VERSION ""

NS_ :

BS_:

BU_: D153 VCU

BO_ 3221225472 VECTOR__INDEPENDENT_SIG_MSG: 0 Vector__XXX
 SG_ VCU_dcBusVoltage : 0|16@0+ (1,0) [0|65535] "" Vector__XXX

BO_ 7 VCU_throttleRegen: 2 VCU
 SG_ VCU_regenPercent : 15|8@0- (1,0) [-128|127] ""  D153
 SG_ VCU_throttlePercent : 7|8@0+ (1,0) [0|255] ""  D153

BO_ 6 VCU_torqueInfo: 4 VCU
 SG_ VCU_throttlePedalTorqueMap : 23|16@0+ (1,0) [0|65535] ""  D153
 SG_ VCU_throttleMapAimSwitch : 7|8@0+ (1,0) [0|255] ""  D153

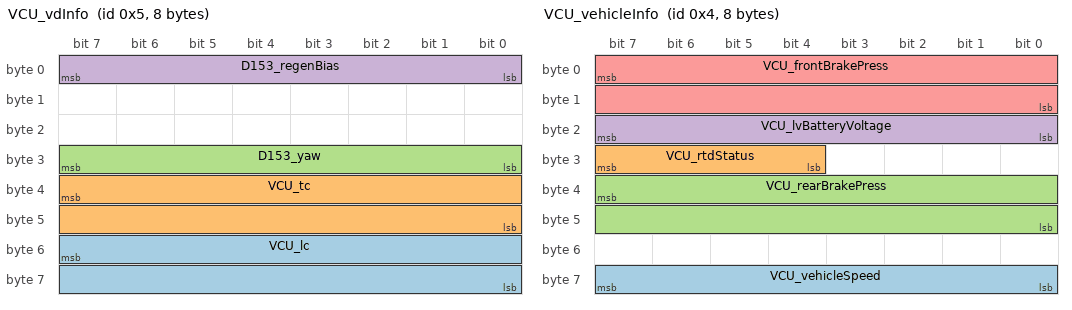
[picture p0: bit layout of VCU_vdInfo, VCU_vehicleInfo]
BO_ 5 VCU_vdInfo: 8 VCU
 SG_ VCU_lc : 55|16@0- (1,0) [-32768|32767] ""  D153
 SG_ VCU_tc : 39|16@0- (1,0) [-32768|32767] ""  D153
 SG_ D153_yaw : 31|8@0+ (1,0) [0|255] ""  VCU
 SG_ D153_regenBias : 7|8@0+ (1,0) [0|255] ""  VCU

BO_ 4 VCU_vehicleInfo: 8 VCU
 SG_ VCU_vehicleSpeed : 63|8@0+ (1,0) [0|255] ""  D153
 SG_ VCU_rtdStatus : 31|4@0- (1,0) [-8|7] ""  D153
 SG_ VCU_rearBrakePress : 39|16@0+ (1,0) [0|65535] ""  D153
 SG_ VCU_lvBatteryVoltage : 23|8@0+ (1,0) [0|255] ""  D153
 SG_ VCU_frontBrakePress : 7|16@0+ (1,0) [0|65535] ""  D153

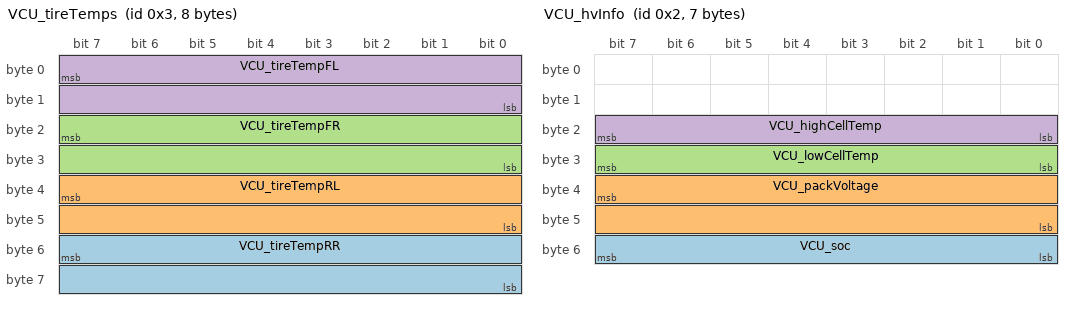
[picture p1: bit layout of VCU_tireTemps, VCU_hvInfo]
BO_ 3 VCU_tireTemps: 8 VCU
 SG_ VCU_tireTempRR : 55|16@0- (1,0) [0|0] ""  D153
 SG_ VCU_tireTempRL : 39|16@0- (1,0) [0|0] ""  D153
 SG_ VCU_tireTempFR : 23|16@0- (1,0) [0|0] ""  D153
 SG_ VCU_tireTempFL : 7|16@0- (1,0) [-32768|32767] ""  D153

BO_ 2 VCU_hvInfo: 7 VCU
 SG_ VCU_soc : 55|8@0+ (1,0) [0|255] ""  D153
 SG_ VCU_packVoltage : 39|16@0+ (1,0) [0|65535] ""  D153
 SG_ VCU_lowCellTemp : 31|8@0- (1,0) [-128|127] ""  D153
 SG_ VCU_highCellTemp : 23|8@0- (1,0) [-128|127] ""  D153

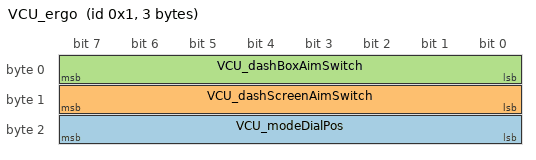
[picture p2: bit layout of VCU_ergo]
BO_ 1 VCU_ergo: 3 VCU
 SG_ VCU_modeDialPos : 23|8@0+ (1,0) [0|255] ""  D153
 SG_ VCU_dashScreenAimSwitch : 15|8@0+ (1,0) [0|255] ""  D153
 SG_ VCU_dashBoxAimSwitch : 7|8@0+ (1,0) [0|255] ""  D153

CM_ BO_ 3221225472 "This is a message for not used signals, created by Vector CANdb++ DBC OLE DB Provider.";
BA_DEF_  "BusType" STRING ;
BA_DEF_DEF_  "BusType" "CAN";
